VERSION ""

NS_ :

BS_:

BU_: SDM102

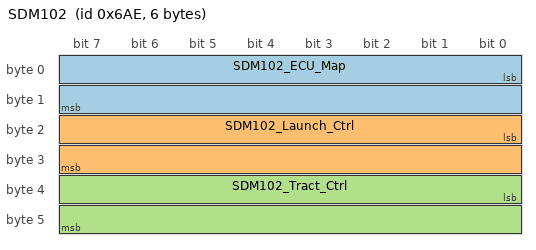
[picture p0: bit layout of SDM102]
BO_ 1710 SDM102: 6 SDM102
 SG_ SDM102_ECU_Map : 0|16@1- (1,0) [0|0] "" Vector__XXX
 SG_ SDM102_Launch_Ctrl : 16|16@1- (1,0) [0|0] "" Vector__XXX
 SG_ SDM102_Tract_Ctrl : 32|16@1- (1,0) [0|0] "" Vector__XXX
